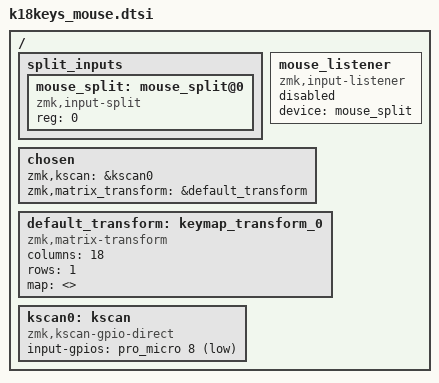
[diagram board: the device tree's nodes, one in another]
/*
 * Copyright (c) 2020 Pete Johanson
 *
 * SPDX-License-Identifier: MIT
 */

#include <dt-bindings/zmk/matrix_transform.h>

/ {
    split_inputs {
        #address-cells = <1>;
        #size-cells = <0>;

        mouse_split: mouse_split@0 {
            compatible = "zmk,input-split";
            reg = <0>;
        };
    };

    mouse_listener: mouse_listener {
        compatible = "zmk,input-listener";
        status = "disabled";
        device = <&mouse_split>;
    };

    chosen {
        zmk,kscan = &kscan0;
        zmk,matrix_transform = &default_transform;
    };

    default_transform: keymap_transform_0 {
        compatible = "zmk,matrix-transform";
        columns = <18>;
        rows = <1>;
        map = <>;
    };

    kscan0: kscan {
        compatible = "zmk,kscan-gpio-direct";

        input-gpios = <&pro_micro  8 (GPIO_ACTIVE_LOW | GPIO_PULL_UP)>;
    };
};
